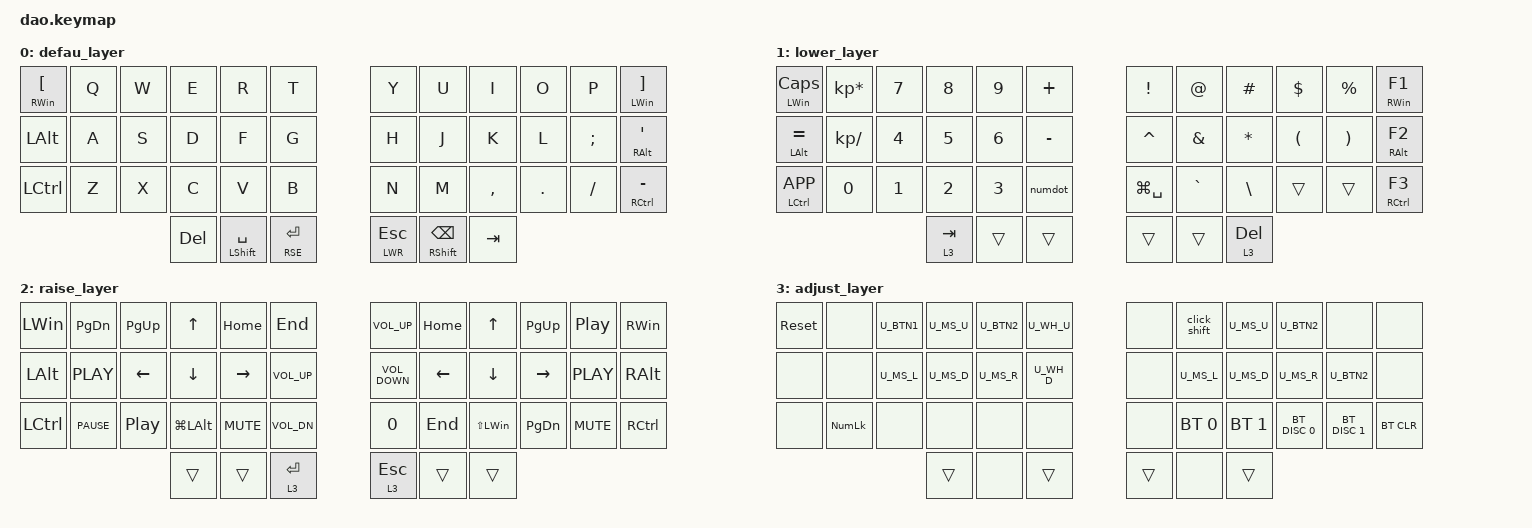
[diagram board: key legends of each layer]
/*
 * Copyright (c) 2020 The ZMK Contributors
 *
 * SPDX-License-Identifier: MIT
 */
#include <behaviors.dtsi>
#include <dt-bindings/zmk/keys.h>
#include <dt-bindings/zmk/bt.h>
#include <dt-bindings/zmk/mouse.h>
#include <dt-bindings/zmk/ext_power.h>
#define DEF 0
#define LWR 1
#define RSE 2
#define ADJ 3
/* Adding Mouse */
#include "mouse.dtsi"
&lt { quick_tap_ms = <220>; };
&mt { quick_tap_ms = <350>; };
/ {
    macros {
        numdot: numdot {
            label = "ZM_numdot";
            compatible = "zmk,behavior-macro";
            #binding-cells = <0>;
            wait-ms = <40>;
            tap-ms = <40>;
            bindings =
                <&macro_press>,
                <&kp LALT>,
                <&macro_tap>,
                <&kp KP_N4 &kp KP_N6>,
                <&macro_release>,
                <&kp LALT>;
        };
        grtsgn: grtsgn {
            label = "ZM_grtsgn";
            compatible = "zmk,behavior-macro";
            #binding-cells = <0>;
            wait-ms = <40>;
            tap-ms = <40>;
            bindings =
                <&macro_press>,
                <&kp LALT>,
                <&macro_tap>,
                <&kp KP_N6 &kp KP_N2>,
                <&macro_release>,
                <&kp LALT>;
        };
        click_shift: click_shift {
            compatible = "zmk,behavior-macro";
            #binding-cells = <0>; 
            wait-ms = <40>;
            tap-ms = <40>;
            bindings
                = <&macro_press &kp LSHFT>
                , <&macro_tap U_BTN1>
                , <&macro_release &kp LSHFT>;
        };
    };
};
/ {
        keymap {
                compatible = "zmk,keymap";
                defau_layer {
                        bindings = <
  &mt RWIN LBKT   &kp Q &kp W &kp E &kp R &kp T               &kp Y  &kp U  &kp I     &kp O   &kp P    &mt LWIN RBKT
  &kp LALT        &kp A &kp S &kp D &kp F &kp G               &kp H  &kp J  &kp K     &kp L   &kp SEMI &mt RALT SQT
  &kp LCTRL       &kp Z &kp X &kp C &kp V &kp B               &kp N  &kp M  &kp COMMA &kp DOT &kp FSLH &mt RCTRL MINUS
          &kp DEL  &mt LSHIFT SPACE &lt RSE RET               &lt LWR ESC   &mt RSHFT BSPC    &kp TAB 
                        >;
                };
        lower_layer {
            bindings = <
&mt LWIN CAPS    &kp KP_MULTIPLY  &kp N7  &kp N8     &kp N9  &kp PLUS   &kp EXCL       &kp AT    &kp HASH   &kp DLLR  &kp PRCNT  &mt RWIN F1
&mt LALT EQUAL   &kp KP_SLASH     &kp N4  &kp N5     &kp N6  &kp MINUS  &kp CARET      &kp AMPS  &kp STAR   &kp LPAR  &kp RPAR   &mt RALT F2
&mt LCTRL K_APP  &kp N0           &kp N1  &kp N2     &kp N3  &numdot    &kp LG(SPACE)  &kp GRAVE &kp BSLH   &trans    &trans     &mt RCTRL F3
                                          &lt 3 TAB  &trans  &trans     &trans         &trans    &lt 3 DEL
            >;
        };
        raise_layer {
            bindings = <
&kp LWIN   &kp PG_DN    &kp PG_UP  &kp UP_ARROW  &kp HOME   &kp END       &kp C_VOL_UP       &kp HOME  &kp UP            &kp PG_UP  &kp C_PP    &kp RWIN
&kp LALT   &kp C_PLAY   &kp LEFT   &kp DOWN      &kp RIGHT  &kp C_VOL_UP  &kp C_VOLUME_DOWN  &kp LEFT  &kp DOWN          &kp RIGHT  &kp C_PLAY  &kp RALT
&kp LCTRL  &kp C_PAUSE  &kp C_PP   &kp LG(LALT)  &kp C_MUTE &kp C_VOL_DN  &kp N0             &kp END   &kp LS(LEFT_WIN)  &kp PG_DN  &kp C_MUTE  &kp RCTRL
                                   &trans        &trans     &lt 3 RET     &lt 3 ESC          &trans    &trans
            >;
        };
        adjust_layer {
            bindings = <
&sys_reset   &none       U_BTN1          U_MS_U          U_BTN2          U_WH_U            &none             &click_shift    U_MS_U          U_BTN2           &none          &none
&none        &none       U_MS_L          U_MS_D          U_MS_R          U_WH_D            &none             U_MS_L          U_MS_D          U_MS_R           U_BTN2         &none
&none        &kp KP_NUM  &none           &none           &none           &none             &none             &bt BT_SEL 0    &bt BT_SEL 1    &bt BT_DISC 0    &bt BT_DISC 1  &bt BT_CLR
                                         &trans          &none           &trans            &trans            &none           &trans
            >;
        };
    };
};
